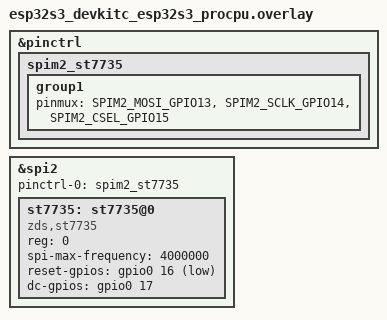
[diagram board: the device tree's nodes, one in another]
/*
 * ESP32-S3-DevKitC-1: SPI2 (GPSPI2) bus wired to an ST7735 128x160
 * color TFT (generic "green tab" 1.8" SPI TFT breakout).
 *
 * Like the Nokia 5110 in Lab 07, this module has no MISO line - it's
 * write-only - so only MOSI, SCLK, and hardware CS0 are configured.
 *
 * RST and DC are plain GPIOs (not part of the SPI pinctrl group),
 * matching the same "reset-gpios"/"dc-gpios" naming convention used
 * in Lab 07 and in Zephyr's own mipi-dbi-spi display binding.
 *
 * spi-max-frequency is 4 MHz - see the comment at the top of main.c
 * for why this is higher than Lab 07's 1 MHz.
 */

#include <zephyr/dt-bindings/gpio/gpio.h>

&pinctrl {
    spim2_st7735: spim2_st7735 {
        group1 {
            pinmux = <SPIM2_MOSI_GPIO13>, <SPIM2_SCLK_GPIO14>, <SPIM2_CSEL_GPIO15>;
        };
    };
};

&spi2 {
    #address-cells = <1>;
    #size-cells = <0>;
    status = "okay";
    pinctrl-0 = <&spim2_st7735>;
    pinctrl-names = "default";

    st7735: st7735@0 {
        compatible = "zds,st7735";
        reg = <0>;
        spi-max-frequency = <4000000>;

        /* Active low: physically pulled low to reset the controller. */
        reset-gpios = <&gpio0 16 GPIO_ACTIVE_LOW>;
        /* Active high: driven low for a command byte, high for data. */
        dc-gpios = <&gpio0 17 GPIO_ACTIVE_HIGH>;
    };
};
